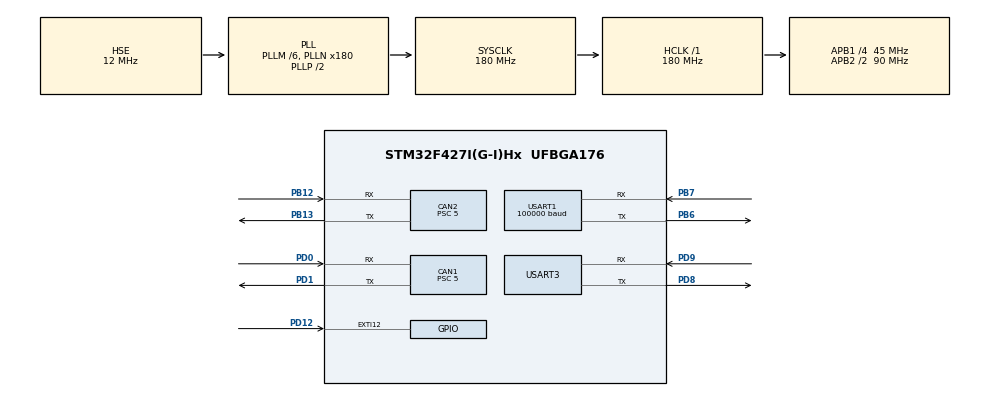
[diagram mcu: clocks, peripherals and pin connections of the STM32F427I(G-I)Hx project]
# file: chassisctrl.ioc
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CAN1.BS1=CAN_BS1_3TQ
CAN1.BS2=CAN_BS2_5TQ
CAN1.CalculateBaudRate=1000000
CAN1.CalculateTimeBit=1000
CAN1.CalculateTimeQuantum=111.11111111111111
CAN1.Prescaler=5
CAN2.BS1=CAN_BS1_3TQ
CAN2.BS2=CAN_BS2_5TQ
CAN2.CalculateBaudRate=1000000
CAN2.CalculateTimeBit=1000
CAN2.CalculateTimeQuantum=111.11111111111111
CAN2.Prescaler=5
Dma.Request0=USART1_RX
Dma.Request1=USART3_RX
Dma.Request2=USART3_TX
Dma.USART1_RX.0.Direction=DMA_PERIPH_TO_MEMORY
Dma.USART1_RX.0.FIFOMode=DMA_FIFOMODE_DISABLE
Dma.USART1_RX.0.Instance=DMA2_Stream2
Dma.USART1_RX.0.MemDataAlignment=DMA_MDATAALIGN_BYTE
Dma.USART1_RX.0.MemInc=DMA_MINC_ENABLE
Dma.USART1_RX.0.Mode=DMA_NORMAL
Dma.USART1_RX.0.PeriphDataAlignment=DMA_PDATAALIGN_BYTE
Dma.USART1_RX.0.PeriphInc=DMA_PINC_DISABLE
Dma.USART1_RX.0.Priority=DMA_PRIORITY_VERY_HIGH
Dma.USART3_RX.1.Direction=DMA_PERIPH_TO_MEMORY
Dma.USART3_RX.1.FIFOMode=DMA_FIFOMODE_DISABLE
Dma.USART3_RX.1.Instance=DMA1_Stream1
Dma.USART3_RX.1.MemDataAlignment=DMA_MDATAALIGN_BYTE
Dma.USART3_RX.1.MemInc=DMA_MINC_ENABLE
Dma.USART3_RX.1.Mode=DMA_NORMAL
Dma.USART3_RX.1.PeriphDataAlignment=DMA_PDATAALIGN_BYTE
Dma.USART3_RX.1.PeriphInc=DMA_PINC_DISABLE
Dma.USART3_RX.1.Priority=DMA_PRIORITY_HIGH
Dma.USART3_TX.2.Direction=DMA_MEMORY_TO_PERIPH
Dma.USART3_TX.2.FIFOMode=DMA_FIFOMODE_DISABLE
Dma.USART3_TX.2.Instance=DMA1_Stream3
Dma.USART3_TX.2.MemDataAlignment=DMA_MDATAALIGN_BYTE
Dma.USART3_TX.2.MemInc=DMA_MINC_ENABLE
Dma.USART3_TX.2.Mode=DMA_NORMAL
Dma.USART3_TX.2.PeriphDataAlignment=DMA_PDATAALIGN_BYTE
Dma.USART3_TX.2.PeriphInc=DMA_PINC_DISABLE
Dma.USART3_TX.2.Priority=DMA_PRIORITY_MEDIUM
FREERTOS.Tasks01=refereeread,24,128,reftask,As weak,NULL,Dynamic,NULL,NULL;devmonitor,24,128,devmoni,As weak,NULL,Dynamic,NULL,NULL;gimbalcontrol,24,128,gimbctrl,As weak,NULL,Dynamic,NULL,NULL;chassiscontrol,24,128,chasctrl,As weak,NULL,Dynamic,NULL,NULL;boardcommunicat,24,128,comutask,As weak,NULL,Dynamic,NULL,NULL;UIdraw,24,128,UIdrawer,As weak,NULL,Dynamic,NULL,NULL;capsctrol,24,128,capsctrl,As weak,NULL,Dynamic,NULL,NULL;roboinfoupdate,24,128,infoupdate,As weak,NULL,Dynamic,NULL,NULL
FREERTOS.configENABLE_FPU=0
IWDG.Prescaler=IWDG_PRESCALER_32
IWDG.Reload=999
Mcu.Family=STM32F4
Mcu.Name=STM32F427I(G-I)Hx
Mcu.Package=UFBGA176
NVIC.CAN1_RX0_IRQn=true\:5\:0\:false\:false\:true\:true\:true\:true\:true
NVIC.CAN2_RX0_IRQn=true\:5\:0\:false\:false\:true\:true\:true\:true\:true
NVIC.DMA1_Stream1_IRQn=true\:5\:0\:false\:false\:false\:true\:false\:true\:true
NVIC.DMA1_Stream3_IRQn=true\:5\:0\:false\:false\:false\:true\:false\:true\:true
NVIC.DMA2_Stream2_IRQn=true\:5\:0\:false\:false\:false\:true\:false\:true\:true
NVIC.EXTI15_10_IRQn=true\:5\:0\:false\:false\:true\:true\:true\:true\:true
NVIC.PriorityGroup=NVIC_PRIORITYGROUP_4
NVIC.USART1_IRQn=true\:5\:0\:false\:false\:false\:true\:true\:true\:true
NVIC.USART3_IRQn=true\:5\:0\:false\:false\:false\:true\:true\:true\:true
PA13.Mode=Serial_Wire
PA13.Signal=SYS_JTMS-SWDIO
PA14.Mode=Serial_Wire
PA14.Signal=SYS_JTCK-SWCLK
PB12.Mode=CAN_Activate
PB12.Signal=CAN2_RX
PB13.Mode=CAN_Activate
PB13.Signal=CAN2_TX
PB6.Mode=Asynchronous
PB6.Signal=USART1_TX
PB7.Mode=Asynchronous
PB7.Signal=USART1_RX
PD0.Mode=CAN_Activate
PD0.Signal=CAN1_RX
PD1.Mode=CAN_Activate
PD1.Signal=CAN1_TX
PD12.GPIO_ModeDefaultEXTI=GPIO_MODE_IT_RISING_FALLING
PD12.GPIO_PuPd=GPIO_PULLDOWN
PD12.Signal=GPXTI12
PD8.Mode=Asynchronous
PD8.Signal=USART3_TX
PD9.Mode=Asynchronous
PD9.Signal=USART3_RX
PH0/OSC_IN.Mode=HSE-External-Oscillator
PH0/OSC_IN.Signal=RCC_OSC_IN
PH1/OSC_OUT.Mode=HSE-External-Oscillator
PH1/OSC_OUT.Signal=RCC_OSC_OUT
ProjectManager.HeapSize=0x200
ProjectManager.StackSize=0x400
ProjectManager.TargetToolchain=Makefile
RCC.48MHZClocksFreq_Value=45000000
RCC.AHBFreq_Value=180000000
RCC.APB1CLKDivider=RCC_HCLK_DIV4
RCC.APB1Freq_Value=45000000
RCC.APB1TimFreq_Value=90000000
RCC.APB2CLKDivider=RCC_HCLK_DIV2
RCC.APB2Freq_Value=90000000
RCC.APB2TimFreq_Value=180000000
RCC.CortexFreq_Value=180000000
RCC.HCLKFreq_Value=180000000
RCC.HSE_VALUE=12000000
RCC.HSI_VALUE=16000000
RCC.LSE_VALUE=32768
RCC.PLLM=6
RCC.PLLN=180
RCC.PLLQ=8
RCC.PLLSourceVirtual=RCC_PLLSOURCE_HSE
RCC.SYSCLKFreq_VALUE=180000000
RCC.SYSCLKSource=RCC_SYSCLKSOURCE_PLLCLK
RCC.VCOOutputFreq_Value=360000000
USART1.BaudRate=100000
USART1.VirtualMode=VM_ASYNC
USART3.VirtualMode=VM_ASYNC
VP_FREERTOS_VS_CMSIS_V2.Mode=CMSIS_V2
VP_IWDG_VS_IWDG.Mode=IWDG_Activate
board=custom

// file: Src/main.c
/* USER CODE BEGIN Header */
/**
 ******************************************************************************
 * @file           : main.c
 * @brief          : Main program body
 ******************************************************************************
 * @attention
 *
 * <h2><center>&copy; Copyright (c) 2022 STMicroelectronics.
 * All rights reserved.</center></h2>
 *
 * This software component is licensed by ST under BSD 3-Clause license,
 * the "License"; You may not use this file except in compliance with the
 * License. You may obtain a copy of the License at:
 *                        opensource.org/licenses/BSD-3-Clause
 *
 ******************************************************************************
 */
/* USER CODE END Header */
#include "main.h"
#include "cmsis_os.h"
#include "can.h"
#include "dma.h"
#include "iwdg.h"
#include "usart.h"
#include "gpio.h"

void SystemClock_Config(void);
void MX_FREERTOS_Init(void);

int main(void)
{

  /* MCU Configuration--------------------------------------------------------*/

  /* Reset of all peripherals, Initializes the Flash interface and the Systick. */
  HAL_Init();

  /* Configure the system clock */
  SystemClock_Config();

  /* Initialize all configured peripherals */
  MX_GPIO_Init();
  MX_DMA_Init();
  MX_CAN1_Init();
  MX_CAN2_Init();
  MX_USART1_UART_Init();
  MX_USART3_UART_Init();

  /* USER CODE BEGIN 2 */
  userinit();
  MX_IWDG_Init();
  /* USER CODE END 2 */

  /* Init scheduler */
  osKernelInitialize();  /* Call init function for freertos objects (in freertos.c) */
  MX_FREERTOS_Init();

  /* Start scheduler */
  osKernelStart();

  /* We should never get here as control is now taken by the scheduler */
  /* Infinite loop */
  while (1)
  {

  }
}

void SystemClock_Config(void)
{
  RCC_OscInitTypeDef RCC_OscInitStruct = {0};
  RCC_ClkInitTypeDef RCC_ClkInitStruct = {0};

  /** Configure the main internal regulator output voltage
  */
  __HAL_RCC_PWR_CLK_ENABLE();
  __HAL_PWR_VOLTAGESCALING_CONFIG(PWR_REGULATOR_VOLTAGE_SCALE1);

  /** Initializes the RCC Oscillators according to the specified parameters
  * in the RCC_OscInitTypeDef structure.
  */
  RCC_OscInitStruct.OscillatorType = RCC_OSCILLATORTYPE_LSI|RCC_OSCILLATORTYPE_HSE;
  RCC_OscInitStruct.HSEState = RCC_HSE_ON;
  RCC_OscInitStruct.LSIState = RCC_LSI_ON;
  RCC_OscInitStruct.PLL.PLLState = RCC_PLL_ON;
  RCC_OscInitStruct.PLL.PLLSource = RCC_PLLSOURCE_HSE;
  RCC_OscInitStruct.PLL.PLLM = 6;
  RCC_OscInitStruct.PLL.PLLN = 180;
  RCC_OscInitStruct.PLL.PLLP = RCC_PLLP_DIV2;
  RCC_OscInitStruct.PLL.PLLQ = 8;
  if (HAL_RCC_OscConfig(&RCC_OscInitStruct) != HAL_OK)
  {
    Error_Handler();
  }

  /** Activate the Over-Drive mode
  */
  if (HAL_PWREx_EnableOverDrive() != HAL_OK)
  {
    Error_Handler();
  }

  /** Initializes the CPU, AHB and APB buses clocks
  */
  RCC_ClkInitStruct.ClockType = RCC_CLOCKTYPE_HCLK|RCC_CLOCKTYPE_SYSCLK
                              |RCC_CLOCKTYPE_PCLK1|RCC_CLOCKTYPE_PCLK2;
  RCC_ClkInitStruct.SYSCLKSource = RCC_SYSCLKSOURCE_PLLCLK;
  RCC_ClkInitStruct.AHBCLKDivider = RCC_SYSCLK_DIV1;
  RCC_ClkInitStruct.APB1CLKDivider = RCC_HCLK_DIV4;
  RCC_ClkInitStruct.APB2CLKDivider = RCC_HCLK_DIV2;

  if (HAL_RCC_ClockConfig(&RCC_ClkInitStruct, FLASH_LATENCY_5) != HAL_OK)
  {
    Error_Handler();
  }
}

void Error_Handler(void)
{
  __disable_irq();
  while (1)
  {
  }
}

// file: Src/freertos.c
/* USER CODE BEGIN Header */
/**
 ******************************************************************************
 * File Name          : freertos.c
 * Description        : Code for freertos applications
 ******************************************************************************
 * @attention
 *
 * <h2><center>&copy; Copyright (c) 2022 STMicroelectronics.
 * All rights reserved.</center></h2>
 *
 * This software component is licensed by ST under Ultimate Liberty license
 * SLA0044, the "License"; You may not use this file except in compliance with
 * the License. You may obtain a copy of the License at:
 *                             www.st.com/SLA0044
 *
 ******************************************************************************
 */
/* USER CODE END Header */

#include "FreeRTOS.h"
#include "task.h"
#include "main.h"
#include "cmsis_os.h"

/* Definitions for refereeread */
osThreadId_t refereereadHandle;
const osThreadAttr_t refereeread_attributes = {
  .name = "refereeread",
  .stack_size = 128 * 4,
  .priority = (osPriority_t) osPriorityNormal,
};
/* Definitions for devmonitor */
osThreadId_t devmonitorHandle;
const osThreadAttr_t devmonitor_attributes = {
  .name = "devmonitor",
  .stack_size = 128 * 4,
  .priority = (osPriority_t) osPriorityNormal,
};
/* Definitions for gimbalcontrol */
osThreadId_t gimbalcontrolHandle;
const osThreadAttr_t gimbalcontrol_attributes = {
  .name = "gimbalcontrol",
  .stack_size = 128 * 4,
  .priority = (osPriority_t) osPriorityNormal,
};
/* Definitions for chassiscontrol */
osThreadId_t chassiscontrolHandle;
const osThreadAttr_t chassiscontrol_attributes = {
  .name = "chassiscontrol",
  .stack_size = 128 * 4,
  .priority = (osPriority_t) osPriorityNormal,
};
/* Definitions for boardcommunicat */
osThreadId_t boardcommunicatHandle;
const osThreadAttr_t boardcommunicat_attributes = {
  .name = "boardcommunicat",
  .stack_size = 128 * 4,
  .priority = (osPriority_t) osPriorityNormal,
};
/* Definitions for UIdraw */
osThreadId_t UIdrawHandle;
const osThreadAttr_t UIdraw_attributes = {
  .name = "UIdraw",
  .stack_size = 128 * 4,
  .priority = (osPriority_t) osPriorityNormal,
};
/* Definitions for capsctrol */
osThreadId_t capsctrolHandle;
const osThreadAttr_t capsctrol_attributes = {
  .name = "capsctrol",
  .stack_size = 128 * 4,
  .priority = (osPriority_t) osPriorityNormal,
};
/* Definitions for roboinfoupdate */
osThreadId_t roboinfoupdateHandle;
const osThreadAttr_t roboinfoupdate_attributes = {
  .name = "roboinfoupdate",
  .stack_size = 128 * 4,
  .priority = (osPriority_t) osPriorityNormal,
};

void reftask(void *argument);
void devmoni(void *argument);
void gimbctrl(void *argument);
void chasctrl(void *argument);
void comutask(void *argument);
void UIdrawer(void *argument);
void capsctrl(void *argument);
void infoupdate(void *argument);

void MX_FREERTOS_Init(void); /* (MISRA C 2004 rule 8.1) */

void MX_FREERTOS_Init(void) {

  /* Create the thread(s) */
  /* creation of refereeread */
  refereereadHandle = osThreadNew(reftask, NULL, &refereeread_attributes);

  /* creation of devmonitor */
  devmonitorHandle = osThreadNew(devmoni, NULL, &devmonitor_attributes);

  /* creation of gimbalcontrol */
  gimbalcontrolHandle = osThreadNew(gimbctrl, NULL, &gimbalcontrol_attributes);

  /* creation of chassiscontrol */
  chassiscontrolHandle = osThreadNew(chasctrl, NULL, &chassiscontrol_attributes);

  /* creation of boardcommunicat */
  boardcommunicatHandle = osThreadNew(comutask, NULL, &boardcommunicat_attributes);

  /* creation of UIdraw */
  UIdrawHandle = osThreadNew(UIdrawer, NULL, &UIdraw_attributes);

  /* creation of capsctrol */
  capsctrolHandle = osThreadNew(capsctrl, NULL, &capsctrol_attributes);

  /* creation of roboinfoupdate */
  roboinfoupdateHandle = osThreadNew(infoupdate, NULL, &roboinfoupdate_attributes);

}

__weak void reftask(void *argument)
{
  for (;;)
  {
    osDelay(1);
  }
}

__weak void devmoni(void *argument)
{
  for (;;)
  {
    osDelay(1);
  }
}

__weak void gimbctrl(void *argument)
{
  for (;;)
  {
    osDelay(1);
  }
}

__weak void chasctrl(void *argument)
{
  for (;;)
  {
    osDelay(1);
  }
}

__weak void comutask(void *argument)
{
  for (;;)
  {
    osDelay(1);
  }
}

__weak void UIdrawer(void *argument)
{
  for (;;)
  {
    osDelay(1);
  }
}

__weak void capsctrl(void *argument)
{
  for (;;)
  {
    osDelay(1);
  }
}

__weak void infoupdate(void *argument)
{
  for(;;)
  {
    osDelay(1);
  }
}
